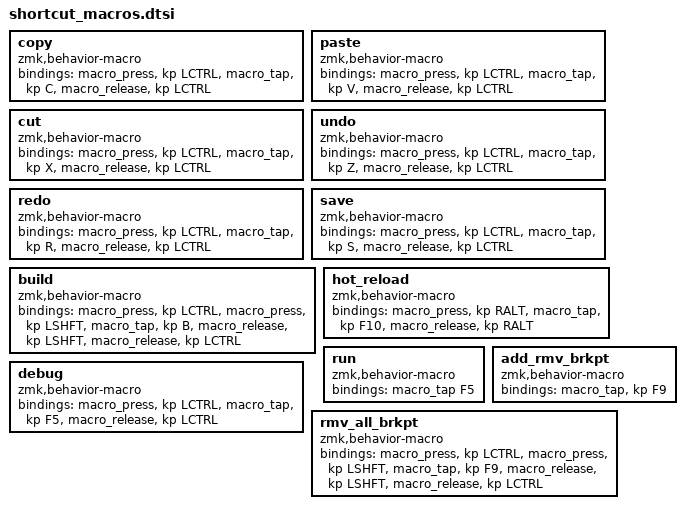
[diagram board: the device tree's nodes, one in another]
    copy: copy {
        compatible = "zmk,behavior-macro";
        #binding-cells = <0>;
        
        bindings
            = <&macro_press   &kp LCTRL>
            , <&macro_tap     &kp C>
            , <&macro_release &kp LCTRL>
        ;
    };

    paste: paste {
        compatible = "zmk,behavior-macro";
        #binding-cells = <0>;
        
        bindings
            = <&macro_press   &kp LCTRL>
            , <&macro_tap     &kp V>
            , <&macro_release &kp LCTRL>
        ;
    };

    cut: cut {
        compatible = "zmk,behavior-macro";
        #binding-cells = <0>;
        
        bindings
            = <&macro_press   &kp LCTRL>
            , <&macro_tap     &kp X>
            , <&macro_release &kp LCTRL>
        ;
    };

    undo: undo {
        compatible = "zmk,behavior-macro";
        #binding-cells = <0>;
        
        bindings
            = <&macro_press   &kp LCTRL>
            , <&macro_tap     &kp Z>
            , <&macro_release &kp LCTRL>
        ;
    };

    redo: redo {
        compatible = "zmk,behavior-macro";
        #binding-cells = <0>;
        
        bindings
            = <&macro_press   &kp LCTRL>
            , <&macro_tap     &kp R>
            , <&macro_release &kp LCTRL>
        ;
    };

    save: save {
        compatible = "zmk,behavior-macro";
        #binding-cells = <0>;
        
        bindings
            = <&macro_press   &kp LCTRL>
            , <&macro_tap     &kp S>
            , <&macro_release &kp LCTRL>
        ;
    };

    build: build {
        compatible = "zmk,behavior-macro";
        #binding-cells = <0>;
        
        bindings
            = <&macro_press   &kp LCTRL>
            , <&macro_press   &kp LSHFT>
            , <&macro_tap     &kp B>
            , <&macro_release &kp LSHFT>
            , <&macro_release &kp LCTRL>
        ;
    };
    
    hot_reload: hot_reload {
        compatible = "zmk,behavior-macro";
        #binding-cells = <0>;
        
        bindings
            = <&macro_press   &kp RALT>
            , <&macro_tap     &kp F10>
            , <&macro_release &kp RALT>
        ;
    };
    
    run: run {
        compatible = "zmk,behavior-macro";
        #binding-cells = <0>;
        
        bindings
            = <&macro_tap F5>
        ;
    };
    
    debug: debug {
        compatible = "zmk,behavior-macro";
        #binding-cells = <0>;
        
        bindings
            = <&macro_press   &kp LCTRL>
            , <&macro_tap     &kp F5>
            , <&macro_release &kp LCTRL>
        ;
    };
    
    add_rmv_brkpt: add_rmv_brkpt {
        compatible = "zmk,behavior-macro";
        #binding-cells = <0>;
        
        bindings
            = <&macro_tap &kp F9>
        ;
    };
    
    rmv_all_brkpt: rmv_all_brkpt {
        compatible = "zmk,behavior-macro";
        #binding-cells = <0>;
        
        bindings
            = <&macro_press   &kp LCTRL>
            , <&macro_press   &kp LSHFT>
            , <&macro_tap     &kp F9>
            , <&macro_release &kp LSHFT>
            , <&macro_release &kp LCTRL>
        ;
    };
